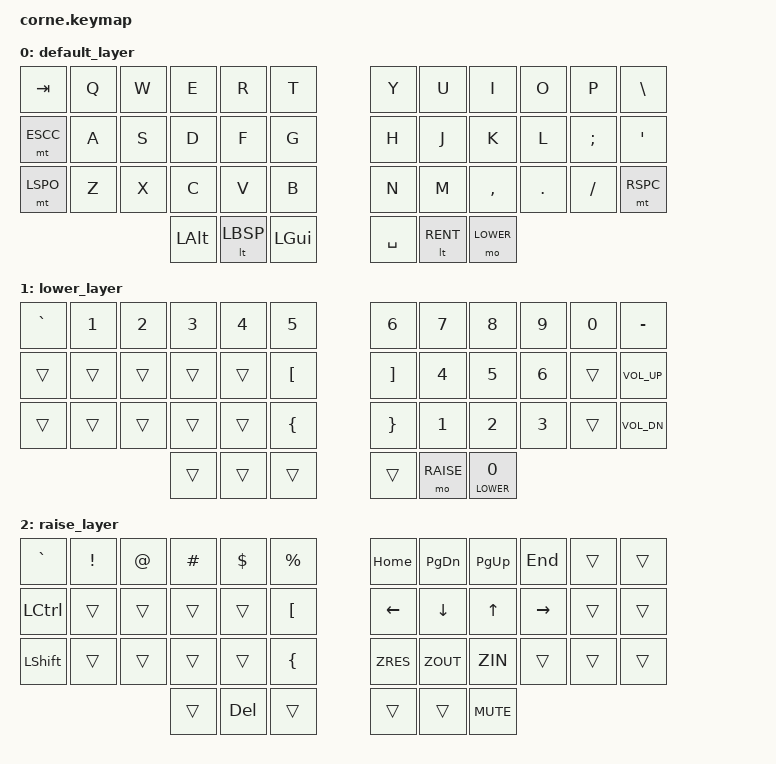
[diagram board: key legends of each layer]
/*
 * Copyright (c) 2020 The ZMK Contributors
 *
 * SPDX-License-Identifier: MIT
 */

#include <behaviors.dtsi>
#include <dt-bindings/zmk/keys.h>
#include <dt-bindings/zmk/bt.h>

#define LOWER 1
#define RAISE 2

// Zoom in and out
#define ZRES LG(N0)
#define ZIN LG(EQUAL)
#define ZOUT LG(MINUS)

// Raise + Enter 
#define RENT RAISE RET
#define LBSP LOWER BSPC

// Escape + Control
#define ESCC LCTRL ESC

// Space Cadet
#define LSPO LSHFT LPAR
#define RSPC RSHFT RPAR


// PHP aliases
// #define SARR MINUS GT
// #define DARR EQUAL GT

/ {
        keymap {
                compatible = "zmk,keymap";

                default_layer {
                        bindings = <
// / ------- | ------- | ------- | ------- | ------- | ------- \    / ------- | ------- | ------- | ------- | ------- | ------- | 
     &kp TAB    &kp Q     &kp W     &kp E     &kp R     &kp T          &kp Y     &kp U     &kp I     &kp O     &kp P    &kp BSLH
// | ------- | ------- | ------- | ------- | ------- | ------- |    | ------- | ------- | ------- | ------- | ------- | ------- |
    &mt ESCC    &kp A     &kp S     &kp D     &kp F     &kp G          &kp H     &kp J     &kp K     &kp L   &kp SEMI   &kp SQT
// | ------- | ------- | ------- | ------- | ------- | ------- |    | ------- | ------- | ------- | ------- | ------- | ------- |
    &mt LSPO    &kp Z     &kp X     &kp C     &kp V     &kp B          &kp N     &kp M   &kp COMMA  &kp DOT   &kp FSLH  &mt RSPC
// \ ------- | ------- | ------- | ------- | ------- | ------- |    | ------- | ------- | ------- | ------- | ------- | ------- /
                                  &kp LALT   &lt LBSP  &kp LGUI      &kp SPACE  &lt RENT  &mo LOWER
//                               \ ------- | ------- | ------- /    \ ------- | ------- | ------- /
                        >;
                };

                lower_layer {
                        bindings = <
// / ------- | ------- | ------- | ------- | ------- | ------- \    / ------- | ------- | ------- | ------- | ------- | ------- |
    &kp GRAVE   &kp N1    &kp N2    &kp N3    &kp N4    &kp N5        &kp N6    &kp N7     &kp N8    &kp N9    &kp N0   &kp MINUS
// | ------- | ------- | ------- | ------- | ------- | ------- |    | ------- | ------- | ------- | ------- | ------- | ------- |
      &trans    &trans     &trans    &trans    &trans  &kp LBKT      &kp RBKT   &kp N4    &kp N5    &kp N6     &trans   &kp K_VOL_UP
// | ------- | ------- | ------- | ------- | ------- | ------- |    | ------- | ------- | ------- | ------- | ------- | ------- |
      &trans    &trans    &trans    &trans    &trans   &kp LBRC       &kp RBRC   &kp N1    &kp N2    &kp N3    &trans   &kp K_VOL_DN
// \ ------- | ------- | ------- | ------- | ------- | ------- |    | ------- | ------- | ------- | ------- | ------- | ------- /
                                   &trans    &trans    &trans         &trans    &mo RAISE &lt LOWER N0
//                               \ ------- | ------- | ------- /    \ ------- | ------- | ------- /
                        >;
                };

                raise_layer {
                        bindings = <
// / ------- | ------- | ------- | ------- | ------- | ------- \    / ------- | ------- | ------- | ------- | ------- | ------- | 
    &kp GRAVE  &kp EXCL   &kp AT   &kp HASH  &kp DLLR  &kp PRCNT      &kp HOME  &kp PG_DN &kp PG_UP &kp END   &trans     &trans
// | ------- | ------- | ------- | ------- | ------- | ------- |    | ------- | ------- | ------- | ------- | ------- | ------- |
   &kp LCTRL   &trans    &trans    &trans    &trans    &kp LBKT       &kp LEFT  &kp DOWN   &kp UP   &kp RIGHT  &trans   &trans
// | ------- | ------- | ------- | ------- | ------- | ------- |    | ------- | ------- | ------- | ------- | ------- | ------- |
   &kp LSHFT   &trans    &trans    &trans   &trans     &kp LBRC       &kp ZRES  &kp ZOUT   &kp ZIN  &trans     &trans   &trans
// \ ------- | ------- | ------- | ------- | ------- | ------- |    | ------- | ------- | ------- | ------- | ------- | ------- /
                                    &trans   &kp DEL   &trans         &trans    &trans    &kp K_MUTE
//                               \ ------- | ------- | ------- /    \ ------- | ------- | ------- /
                        >;
                };
        };
};
